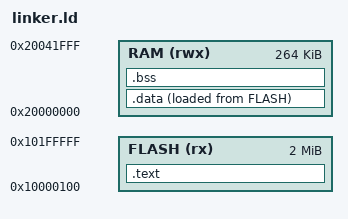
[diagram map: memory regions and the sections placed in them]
ENTRY(Reset_Handler)

MEMORY
{
    FLASH (rx)  : ORIGIN = 0x10000100, LENGTH = 2048K - 0x100
    RAM   (rwx) : ORIGIN = 0x20000000, LENGTH = 264K
}

_stack_top = ORIGIN(RAM) + LENGTH(RAM);

SECTIONS
{
    .text :
    {
        KEEP(*(.vectors))
        *(.text.Reset_Handler)
        *(.text*)
        *(.rodata*)
    } > FLASH

    .data :
    {
        . = ALIGN(4);
        _sdata = .;
        *(.data*)
        . = ALIGN(4);
        _edata = .;
    } > RAM AT > FLASH

    _sidata = LOADADDR(.data);

    .bss (NOLOAD) :
    {
        . = ALIGN(4);
        _sbss = .;
        *(.bss*)
        *(COMMON)
        . = ALIGN(4);
        _ebss = .;
    } > RAM
}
